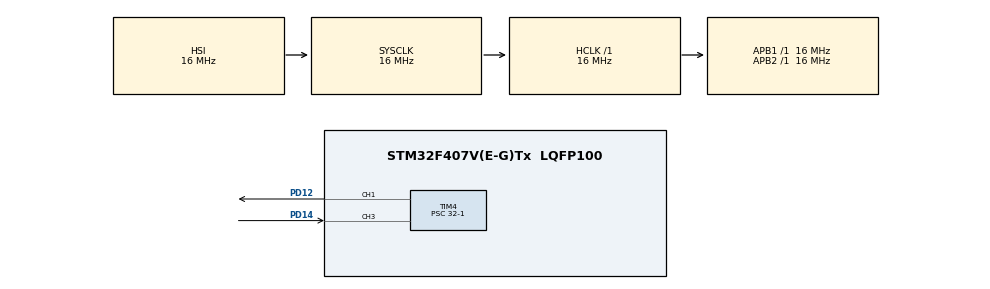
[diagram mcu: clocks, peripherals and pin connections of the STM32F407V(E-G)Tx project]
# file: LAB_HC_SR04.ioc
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Mcu.Family=STM32F4
Mcu.Name=STM32F407V(E-G)Tx
Mcu.Package=LQFP100
NVIC.PriorityGroup=NVIC_PRIORITYGROUP_4
NVIC.TIM4_IRQn=true\:0\:0\:false\:false\:true\:true\:true\:true
PA13.Mode=Serial_Wire
PA13.Signal=SYS_JTMS-SWDIO
PA14.Mode=Serial_Wire
PA14.Signal=SYS_JTCK-SWCLK
PD12.Signal=S_TIM4_CH1
PD14.Signal=S_TIM4_CH3
ProjectManager.HeapSize=0x200
ProjectManager.StackSize=0x400
ProjectManager.TargetToolchain=MDK-ARM V5.32
RCC.AHBFreq_Value=16000000
RCC.APB1Freq_Value=16000000
RCC.APB2Freq_Value=16000000
RCC.CortexFreq_Value=16000000
RCC.HSE_VALUE=25000000
RCC.HSI_VALUE=16000000
RCC.LSE_VALUE=32768
RCC.SYSCLKFreq_VALUE=16000000
RCC.VCOOutputFreq_Value=192000000
SH.S_TIM4_CH1.0=TIM4_CH1,PWM Generation1 CH1
SH.S_TIM4_CH3.0=TIM4_CH3,Input_Capture3_from_TI3
TIM4.Channel-Input_Capture3_from_TI3=TIM_CHANNEL_3
TIM4.Channel-Input_Capture4_from_TI3_63=TIM_CHANNEL_4
TIM4.Channel-PWM\ Generation1\ CH1=TIM_CHANNEL_1
TIM4.ICPolarity_CH4=TIM_INPUTCHANNELPOLARITY_FALLING
TIM4.Period=50000-1
TIM4.Prescaler=32-1
TIM4.Pulse-PWM\ Generation1\ CH1=5-1
VP_TIM4_VS_indirect_ch3.Mode=Input_Capture4_from_TI3_63
board=custom

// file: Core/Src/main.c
/* USER CODE BEGIN Header */
/**
  ******************************************************************************
  * @file           : main.c
  * @brief          : Main program body
  ******************************************************************************
  * @attention
  *
  * Copyright (c) 2022 STMicroelectronics.
  * All rights reserved.
  *
  * This software is licensed under terms that can be found in the LICENSE file
  * in the root directory of this software component.
  * If no LICENSE file comes with this software, it is provided AS-IS.
  *
  ******************************************************************************
  */
/* USER CODE END Header */
#include "main.h"
#include "tim.h"
#include "gpio.h"

/* USER CODE BEGIN PV */
uint32_t distance = 0;
/* USER CODE END PV */

void SystemClock_Config(void);

int main(void)
{

  /* MCU Configuration--------------------------------------------------------*/

  /* Reset of all peripherals, Initializes the Flash interface and the Systick. */
  HAL_Init();

  /* Configure the system clock */
  SystemClock_Config();

  /* Initialize all configured peripherals */
  MX_GPIO_Init();
  MX_TIM4_Init();
  /* USER CODE BEGIN 2 */
  HAL_TIM_Base_Start(&htim4);
  HAL_TIM_PWM_Start(&htim4, TIM_CHANNEL_1);
  HAL_TIM_IC_Start(&htim4,TIM_CHANNEL_3);
  HAL_TIM_IC_Start_IT(&htim4,TIM_CHANNEL_4);

  /* USER CODE END 2 */

  /* Infinite loop */
  /* USER CODE BEGIN WHILE */
  uint32_t t1 = 0;
  uint32_t t2 = 0;
  uint32_t ti = 0;
  while (1)
  {
    t1 = __HAL_TIM_GET_COMPARE(&htim4,TIM_CHANNEL_3);
    t2 = __HAL_TIM_GET_COMPARE(&htim4,TIM_CHANNEL_4);
    if (t2 < t1)
    {
      t2 = t1;
    }
    ti = t2 - t1;
    distance = ti * 2 / 58;
    /* USER CODE END WHILE */

  }
}

void SystemClock_Config(void)
{
  RCC_OscInitTypeDef RCC_OscInitStruct = {0};
  RCC_ClkInitTypeDef RCC_ClkInitStruct = {0};

  /** Configure the main internal regulator output voltage
  */
  __HAL_RCC_PWR_CLK_ENABLE();
  __HAL_PWR_VOLTAGESCALING_CONFIG(PWR_REGULATOR_VOLTAGE_SCALE1);

  /** Initializes the RCC Oscillators according to the specified parameters
  * in the RCC_OscInitTypeDef structure.
  */
  RCC_OscInitStruct.OscillatorType = RCC_OSCILLATORTYPE_HSI;
  RCC_OscInitStruct.HSIState = RCC_HSI_ON;
  RCC_OscInitStruct.HSICalibrationValue = RCC_HSICALIBRATION_DEFAULT;
  RCC_OscInitStruct.PLL.PLLState = RCC_PLL_NONE;
  if (HAL_RCC_OscConfig(&RCC_OscInitStruct) != HAL_OK)
  {
    Error_Handler();
  }

  /** Initializes the CPU, AHB and APB buses clocks
  */
  RCC_ClkInitStruct.ClockType = RCC_CLOCKTYPE_HCLK|RCC_CLOCKTYPE_SYSCLK
                              |RCC_CLOCKTYPE_PCLK1|RCC_CLOCKTYPE_PCLK2;
  RCC_ClkInitStruct.SYSCLKSource = RCC_SYSCLKSOURCE_HSI;
  RCC_ClkInitStruct.AHBCLKDivider = RCC_SYSCLK_DIV1;
  RCC_ClkInitStruct.APB1CLKDivider = RCC_HCLK_DIV1;
  RCC_ClkInitStruct.APB2CLKDivider = RCC_HCLK_DIV1;

  if (HAL_RCC_ClockConfig(&RCC_ClkInitStruct, FLASH_LATENCY_0) != HAL_OK)
  {
    Error_Handler();
  }
}

void Error_Handler(void)
{
  __disable_irq();
  while (1)
  {
  }
}
